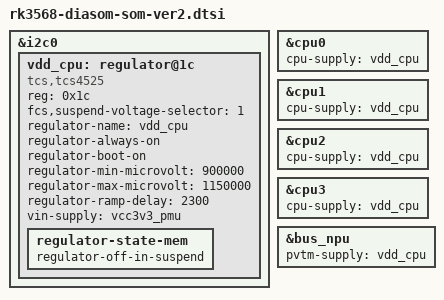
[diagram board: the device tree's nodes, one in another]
// SPDX-License-Identifier: (GPL-2.0+ OR MIT)

&i2c0 {
	vdd_cpu: regulator@1c {
		compatible = "tcs,tcs4525";
		reg = <0x1c>;
		fcs,suspend-voltage-selector = <1>;
		regulator-name = "vdd_cpu";
		regulator-always-on;
		regulator-boot-on;
		regulator-min-microvolt = <900000>;
		regulator-max-microvolt = <1150000>;
		regulator-ramp-delay = <2300>;
		vin-supply = <&vcc3v3_pmu>;

		regulator-state-mem {
			regulator-off-in-suspend;
		};
	};
};

&cpu0 {
	cpu-supply = <&vdd_cpu>;
};

&cpu1 {
	cpu-supply = <&vdd_cpu>;
};

&cpu2 {
	cpu-supply = <&vdd_cpu>;
};

&cpu3 {
	cpu-supply = <&vdd_cpu>;
};

&bus_npu {
	pvtm-supply = <&vdd_cpu>;
};
